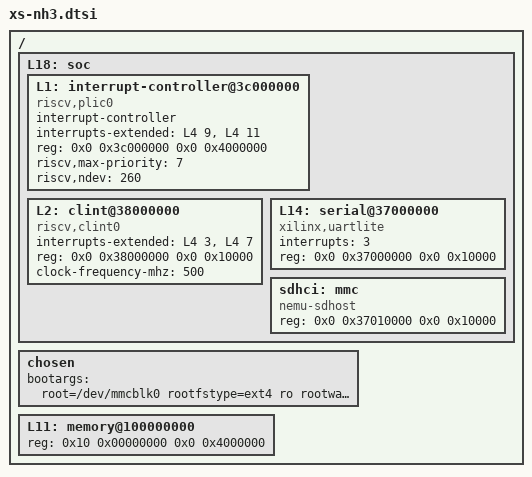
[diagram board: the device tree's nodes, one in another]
/dts-v1/;

/ {
	L18: soc {
		L1: interrupt-controller@3c000000 {
			compatible = "riscv,plic0";
			interrupt-controller;
			interrupts-extended = <&L4 9 &L4 11>;
			reg = <0x0 0x3c000000 0x0 0x4000000>;
			reg-names = "control";
			riscv,max-priority = <7>;
			riscv,ndev = <260>;
		};
		L2: clint@38000000 {
			compatible = "riscv,clint0";
			interrupts-extended = <&L4 3 &L4 7>;
			reg = <0x0 0x38000000 0x0 0x10000>;
			reg-names = "control";
			clock-frequency-mhz = <500>;
		};
		L14: serial@37000000 {
			compatible = "xilinx,uartlite";
			//interrupt-parent = <&L1>;
			interrupts = <3>;
			reg = <0x0 0x37000000 0x0 0x10000>;
			reg-names = "control";
		};
		sdhci: mmc {
			compatible = "nemu-sdhost";
			reg = <0x0 0x37010000 0x0 0x10000>;
		};
	};
	chosen {
		bootargs = "root=/dev/mmcblk0 rootfstype=ext4 ro rootwait earlycon";
	};
	L11: memory@100000000 {
		device_type = "memory";
		reg = <0x10 0x00000000 0x0 0x4000000>;
	};
};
